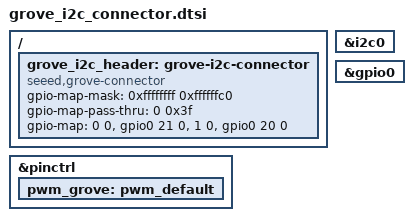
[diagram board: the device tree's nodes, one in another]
/*
 * Copyright (c) 2023-2025 TiaC Systems
 * SPDX-License-Identifier: Apache-2.0
 */

#include <bridle/dt-bindings/seeed_grove_pwms_defaults.h>

/ {
	grove_i2c_header: grove-i2c-connector {
		compatible = "seeed,grove-connector";
		#gpio-cells = <2>;
		gpio-map-mask = <0xffffffff 0xffffffc0>;
		gpio-map-pass-thru = <0 0x3f>;
		gpio-map = <0 0 &gpio0 21 0>,	/* GP21/PWM2CHB(5) / I2C0-SCL */
			   <1 0 &gpio0 20 0>;	/* GP20/PWM2CHA(4) / I2C0-SDA */
	};
};

grove_i2c: &i2c0 {
	status = "okay";
};

&gpio0 {
	status = "okay";
};

&pinctrl {
	pwm_grove: pwm_default {};
};

#undef GROVE_PWM_D20_SLOW
#define GROVE_PWM_D20_SLOW				\
	&pwm {						\
		divider-frac-2 = <15>;			\
		divider-int-2 = <255>;			\
	};

#undef GROVE_PWM_D20_ENABLE
#define GROVE_PWM_D20_ENABLE				\
	&pwm {						\
		status = "okay";			\
	};

#undef GROVE_PWM_D20_PINCTRL
#define GROVE_PWM_D20_PINCTRL				\
	&pwm_grove {					\
		group20 {				\
			pinmux = <PWM_2A_P20>;		\
		};					\
	};

#undef GROVE_PWM_D21_SLOW
#define GROVE_PWM_D21_SLOW				\
	&pwm {						\
		divider-frac-2 = <15>;			\
		divider-int-2 = <255>;			\
	};

#undef GROVE_PWM_D21_ENABLE
#define GROVE_PWM_D21_ENABLE				\
	&pwm {						\
		status = "okay";			\
	};

#undef GROVE_PWM_D21_PINCTRL
#define GROVE_PWM_D21_PINCTRL				\
	&pwm_grove {					\
		group21 {				\
			pinmux = <PWM_2B_P21>;		\
		};					\
	};
